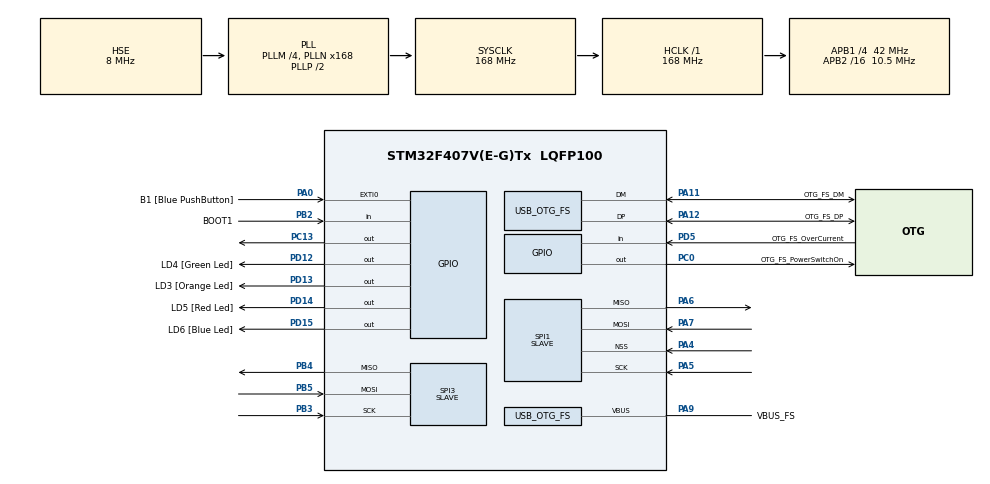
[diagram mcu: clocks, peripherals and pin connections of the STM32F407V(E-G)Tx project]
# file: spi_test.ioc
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Mcu.Family=STM32F4
Mcu.Name=STM32F407V(E-G)Tx
Mcu.Package=LQFP100
NVIC.OTG_FS_IRQn=true\:0\:0\:false\:false\:true\:true\:true\:true
NVIC.PriorityGroup=NVIC_PRIORITYGROUP_0
NVIC.TIM2_IRQn=true\:0\:0\:false\:false\:true\:true\:true\:true
PA0-WKUP.GPIO_Label=B1 [Blue PushButton]
PA0-WKUP.GPIO_ModeDefaultEXTI=GPIO_MODE_EVT_RISING
PA0-WKUP.GPIO_PuPd=GPIO_NOPULL
PA0-WKUP.Signal=GPXTI0
PA10.GPIO_Label=OTG_FS_ID
PA10.GPIO_Mode=GPIO_MODE_AF_PP
PA10.GPIO_PuPd=GPIO_NOPULL
PA10.GPIO_Speed=GPIO_SPEED_FREQ_LOW
PA10.Signal=USB_OTG_FS_ID
PA11.GPIO_Label=OTG_FS_DM
PA11.GPIO_Mode=GPIO_MODE_AF_PP
PA11.GPIO_PuPd=GPIO_NOPULL
PA11.GPIO_Speed=GPIO_SPEED_FREQ_LOW
PA11.Mode=Device_Only
PA11.Signal=USB_OTG_FS_DM
PA12.GPIO_Label=OTG_FS_DP
PA12.GPIO_Mode=GPIO_MODE_AF_PP
PA12.GPIO_PuPd=GPIO_NOPULL
PA12.GPIO_Speed=GPIO_SPEED_FREQ_LOW
PA12.Mode=Device_Only
PA12.Signal=USB_OTG_FS_DP
PA13.GPIO_Label=SWDIO
PA13.Signal=SYS_JTMS-SWDIO
PA4.GPIO_Speed=GPIO_SPEED_FREQ_LOW
PA4.Mode=NSS_Signal_Hard_Input
PA4.Signal=SPI1_NSS
PA5.GPIO_Speed=GPIO_SPEED_FREQ_LOW
PA5.Mode=Full_Duplex_Slave
PA5.Signal=SPI1_SCK
PA6.Mode=Full_Duplex_Slave
PA6.Signal=SPI1_MISO
PA7.GPIO_Speed=GPIO_SPEED_FREQ_LOW
PA7.Mode=Full_Duplex_Slave
PA7.Signal=SPI1_MOSI
PA9.GPIO_Label=VBUS_FS
PA9.GPIO_Mode=GPIO_MODE_INPUT
PA9.GPIO_PuPd=GPIO_NOPULL
PA9.Mode=Activate_VBUS
PA9.Signal=USB_OTG_FS_VBUS
PB2.GPIO_Label=BOOT1
PB2.GPIO_Mode=GPIO_MODE_INPUT
PB2.GPIO_PuPd=GPIO_NOPULL
PB2.Signal=GPIO_Input
PB3.Mode=Full_Duplex_Slave
PB3.Signal=SPI3_SCK
PB4.Mode=Full_Duplex_Slave
PB4.Signal=SPI3_MISO
PB5.Mode=Full_Duplex_Slave
PB5.Signal=SPI3_MOSI
PC0.GPIO_Label=OTG_FS_PowerSwitchOn
PC0.GPIO_PuPd=GPIO_NOPULL
PC0.GPIO_Speed=GPIO_SPEED_FREQ_LOW
PC0.PinState=GPIO_PIN_SET
PC0.Signal=GPIO_Output
PC13-ANTI_TAMP.Signal=GPIO_Output
PC14-OSC32_IN.GPIO_Label=PC14-OSC32_IN
PC14-OSC32_IN.Mode=LSE-External-Oscillator
PC14-OSC32_IN.Signal=RCC_OSC32_IN
PC15-OSC32_OUT.GPIO_Label=PC15-OSC32_OUT
PC15-OSC32_OUT.Mode=LSE-External-Oscillator
PC15-OSC32_OUT.Signal=RCC_OSC32_OUT
PC3.GPIO_Label=PDM_OUT [MP45DT02_DOUT]
PC3.GPIO_Mode=GPIO_MODE_AF_PP
PC3.GPIO_PuPd=GPIO_NOPULL
PC3.GPIO_Speed=GPIO_SPEED_FREQ_LOW
PC3.Signal=I2S2_SD
PD12.GPIO_Label=LD4 [Green Led]
PD12.GPIO_PuPd=GPIO_NOPULL
PD12.GPIO_Speed=GPIO_SPEED_FREQ_LOW
PD12.Signal=GPIO_Output
PD13.GPIO_Label=LD3 [Orange Led]
PD13.GPIO_PuPd=GPIO_NOPULL
PD13.GPIO_Speed=GPIO_SPEED_FREQ_LOW
PD13.Signal=GPIO_Output
PD14.GPIO_Label=LD5 [Red Led]
PD14.GPIO_PuPd=GPIO_NOPULL
PD14.GPIO_Speed=GPIO_SPEED_FREQ_LOW
PD14.Signal=GPIO_Output
PD15.GPIO_Label=LD6 [Blue Led]
PD15.GPIO_PuPd=GPIO_NOPULL
PD15.GPIO_Speed=GPIO_SPEED_FREQ_LOW
PD15.Signal=GPIO_Output
PD5.GPIO_Label=OTG_FS_OverCurrent
PD5.GPIO_Mode=GPIO_MODE_INPUT
PD5.GPIO_PuPd=GPIO_NOPULL
PD5.Signal=GPIO_Input
PH0-OSC_IN.GPIO_Label=PH0-OSC_IN
PH0-OSC_IN.Mode=HSE-External-Oscillator
PH0-OSC_IN.Signal=RCC_OSC_IN
PH1-OSC_OUT.GPIO_Label=PH1-OSC_OUT
PH1-OSC_OUT.Mode=HSE-External-Oscillator
PH1-OSC_OUT.Signal=RCC_OSC_OUT
ProjectManager.HeapSize=0x200
ProjectManager.StackSize=0x400
ProjectManager.TargetToolchain=STM32CubeIDE
RCC.48MHZClocksFreq_Value=48000000
RCC.AHBFreq_Value=168000000
RCC.APB1CLKDivider=RCC_HCLK_DIV4
RCC.APB1Freq_Value=42000000
RCC.APB1TimFreq_Value=84000000
RCC.APB2CLKDivider=RCC_HCLK_DIV16
RCC.APB2Freq_Value=10500000
RCC.APB2TimFreq_Value=21000000
RCC.CortexFreq_Value=168000000
RCC.HCLKFreq_Value=168000000
RCC.HSE_VALUE=8000000
RCC.HSI_VALUE=16000000
RCC.PLLM=4
RCC.PLLN=168
RCC.PLLQ=7
RCC.SYSCLKFreq_VALUE=168000000
RCC.SYSCLKSource=RCC_SYSCLKSOURCE_PLLCLK
RCC.VCOOutputFreq_Value=336000000
SPI1.Direction=SPI_DIRECTION_2LINES
SPI1.Mode=SPI_MODE_SLAVE
SPI1.VirtualNSS=VM_NSSHARD
SPI1.VirtualType=VM_SLAVE
SPI3.Direction=SPI_DIRECTION_2LINES
SPI3.Mode=SPI_MODE_SLAVE
SPI3.VirtualType=VM_SLAVE
USB_DEVICE.CLASS_NAME_FS=CDC
USB_DEVICE.VirtualMode-CDC_FS=Cdc
USB_DEVICE.VirtualModeFS=Cdc_FS
USB_OTG_FS.VirtualMode=Device_Only
VP_TIM2_VS_ClockSourceINT.Mode=Internal
VP_USB_DEVICE_VS_USB_DEVICE_CDC_FS.Mode=CDC_FS
board=STM32F407G-DISC1

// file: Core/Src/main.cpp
/* USER CODE BEGIN Header */
/**
  ******************************************************************************
  * @file           : main.c
  * @brief          : Main program body
  ******************************************************************************
  * @attention
  *
  * Copyright (c) 2023 STMicroelectronics.
  * All rights reserved.
  *
  * This software is licensed under terms that can be found in the LICENSE file
  * in the root directory of this software component.
  * If no LICENSE file comes with this software, it is provided AS-IS.
  *
  ******************************************************************************
  */
/* USER CODE END Header */
#include "main.h"
#include "usb_device.h"
#include "local.hpp"
#include "spi.hpp"

SPI_HandleTypeDef hspi1;
SPI_HandleTypeDef hspi3;
DMA_HandleTypeDef hdma_spi1_rx;
DMA_HandleTypeDef hdma_spi1_tx;

TIM_HandleTypeDef htim2;

void SystemClock_Config(void);
static void MX_GPIO_Init(void);
static void MX_DMA_Init(void);
static void MX_TIM2_Init(void);
static void MX_SPI1_Init(void);
static void MX_SPI3_Init(void);

int main(void)
{

  /* MCU Configuration--------------------------------------------------------*/

  /* Reset of all peripherals, Initializes the Flash interface and the Systick. */
  HAL_Init();

  /* Configure the system clock */
  SystemClock_Config();

  /* USER CODE END SysInit */

  /* Initialize all configured peripherals */
  MX_GPIO_Init();
  MX_DMA_Init();
  MX_USB_DEVICE_Init();
  MX_TIM2_Init();
  MX_SPI1_Init();
  MX_SPI3_Init();

  /* Infinite loop */
  /* USER CODE BEGIN WHILE */
  uint8_t tx = 0xAA;
  uint8_t rx = 0xBB;
  //uprintf("\r\n"); HAL_Delay(1000);
  for (int i=3; i>0; i--) {
    uprintf("slave start %d\r\n", i);
    HAL_GPIO_TogglePin(LD4_GPIO_Port, LD4_Pin); // green
    HAL_Delay(1000);
  }
  uprintf("\r\n"); HAL_Delay(1000);
  uprintf("\r\n"); HAL_Delay(1000);
  uprintf("\r\n"); HAL_Delay(1000);

  while (1)
  {
    /* USER CODE END WHILE */
    /* USER CODE BEGIN 3 */
      //HAL_GPIO_TogglePin(LD4_GPIO_Port, LD4_Pin); // green
      //HAL_GPIO_TogglePin(GPIOA, GPIO_PIN_6);
      //HAL_Delay(1000);
      PAL_SPI_TransmitReceive(&hspi1, &tx, &rx, 1, HAL_MAX_DELAY);
      uprintf("slave: tx=%d rx=%d -----------------------------------------------------------\r\n", tx, rx);
      HAL_GPIO_TogglePin(LD4_GPIO_Port, LD4_Pin); // green
      tx = rx;
  }
  /* USER CODE END 3 */
}

void SystemClock_Config(void)
{
  RCC_OscInitTypeDef RCC_OscInitStruct = {0};
  RCC_ClkInitTypeDef RCC_ClkInitStruct = {0};

  /** Configure the main internal regulator output voltage
  */
  __HAL_RCC_PWR_CLK_ENABLE();
  __HAL_PWR_VOLTAGESCALING_CONFIG(PWR_REGULATOR_VOLTAGE_SCALE1);

  /** Initializes the RCC Oscillators according to the specified parameters
  * in the RCC_OscInitTypeDef structure.
  */
  RCC_OscInitStruct.OscillatorType = RCC_OSCILLATORTYPE_HSE;
  RCC_OscInitStruct.HSEState = RCC_HSE_ON;
  RCC_OscInitStruct.PLL.PLLState = RCC_PLL_ON;
  RCC_OscInitStruct.PLL.PLLSource = RCC_PLLSOURCE_HSE;
  RCC_OscInitStruct.PLL.PLLM = 4;
  RCC_OscInitStruct.PLL.PLLN = 168;
  RCC_OscInitStruct.PLL.PLLP = RCC_PLLP_DIV2;
  RCC_OscInitStruct.PLL.PLLQ = 7;
  if (HAL_RCC_OscConfig(&RCC_OscInitStruct) != HAL_OK)
  {
    Error_Handler();
  }

  /** Initializes the CPU, AHB and APB buses clocks
  */
  RCC_ClkInitStruct.ClockType = RCC_CLOCKTYPE_HCLK|RCC_CLOCKTYPE_SYSCLK
                              |RCC_CLOCKTYPE_PCLK1|RCC_CLOCKTYPE_PCLK2;
  RCC_ClkInitStruct.SYSCLKSource = RCC_SYSCLKSOURCE_PLLCLK;
  RCC_ClkInitStruct.AHBCLKDivider = RCC_SYSCLK_DIV1;
  RCC_ClkInitStruct.APB1CLKDivider = RCC_HCLK_DIV4;
  RCC_ClkInitStruct.APB2CLKDivider = RCC_HCLK_DIV16;

  if (HAL_RCC_ClockConfig(&RCC_ClkInitStruct, FLASH_LATENCY_5) != HAL_OK)
  {
    Error_Handler();
  }
}

static void MX_SPI1_Init(void)
{

  /* SPI1 parameter configuration*/
  hspi1.Instance = SPI1;
  hspi1.Init.Mode = SPI_MODE_SLAVE;
  hspi1.Init.Direction = SPI_DIRECTION_2LINES;
  hspi1.Init.DataSize = SPI_DATASIZE_8BIT;
  //hspi1.Init.DataSize = SPI_DATASIZE_16BIT;
  hspi1.Init.CLKPolarity = SPI_POLARITY_LOW;
  hspi1.Init.CLKPhase = SPI_PHASE_1EDGE;
  hspi1.Init.NSS = SPI_NSS_HARD_INPUT;
  //hspi1.Init.NSS = SPI_NSS_SOFT;
  hspi1.Init.FirstBit = SPI_FIRSTBIT_MSB;
  hspi1.Init.TIMode = SPI_TIMODE_DISABLE;
  hspi1.Init.CRCCalculation = SPI_CRCCALCULATION_DISABLE;
  hspi1.Init.CRCPolynomial = 10;
  if (HAL_SPI_Init(&hspi1) != HAL_OK)
  {
    Error_Handler();
  }

}

static void MX_SPI3_Init(void)
{

  /* SPI3 parameter configuration*/
  hspi3.Instance = SPI3;
  hspi3.Init.Mode = SPI_MODE_SLAVE;
  hspi3.Init.Direction = SPI_DIRECTION_2LINES;
  hspi3.Init.DataSize = SPI_DATASIZE_8BIT;
  hspi3.Init.CLKPolarity = SPI_POLARITY_LOW;
  hspi3.Init.CLKPhase = SPI_PHASE_1EDGE;
  hspi3.Init.NSS = SPI_NSS_SOFT;
  hspi3.Init.FirstBit = SPI_FIRSTBIT_MSB;
  hspi3.Init.TIMode = SPI_TIMODE_DISABLE;
  hspi3.Init.CRCCalculation = SPI_CRCCALCULATION_DISABLE;
  hspi3.Init.CRCPolynomial = 10;
  if (HAL_SPI_Init(&hspi3) != HAL_OK)
  {
    Error_Handler();
  }

}

static void MX_TIM2_Init(void)
{

  TIM_ClockConfigTypeDef sClockSourceConfig = {0};
  TIM_MasterConfigTypeDef sMasterConfig = {0};

  htim2.Instance = TIM2;
  htim2.Init.Prescaler = 0;
  htim2.Init.CounterMode = TIM_COUNTERMODE_UP;
  htim2.Init.Period = 4294967295;
  htim2.Init.ClockDivision = TIM_CLOCKDIVISION_DIV1;
  htim2.Init.AutoReloadPreload = TIM_AUTORELOAD_PRELOAD_DISABLE;
  if (HAL_TIM_Base_Init(&htim2) != HAL_OK)
  {
    Error_Handler();
  }
  sClockSourceConfig.ClockSource = TIM_CLOCKSOURCE_INTERNAL;
  if (HAL_TIM_ConfigClockSource(&htim2, &sClockSourceConfig) != HAL_OK)
  {
    Error_Handler();
  }
  sMasterConfig.MasterOutputTrigger = TIM_TRGO_RESET;
  sMasterConfig.MasterSlaveMode = TIM_MASTERSLAVEMODE_DISABLE;
  if (HAL_TIMEx_MasterConfigSynchronization(&htim2, &sMasterConfig) != HAL_OK)
  {
    Error_Handler();
  }

}

static void MX_DMA_Init(void)
{

  /* DMA controller clock enable */
  __HAL_RCC_DMA2_CLK_ENABLE();

  /* DMA interrupt init */
  /* DMA2_Stream0_IRQn interrupt configuration */
  HAL_NVIC_SetPriority(DMA2_Stream0_IRQn, 0, 0);
  HAL_NVIC_EnableIRQ(DMA2_Stream0_IRQn);
  /* DMA2_Stream3_IRQn interrupt configuration */
  HAL_NVIC_SetPriority(DMA2_Stream3_IRQn, 0, 0);
  HAL_NVIC_EnableIRQ(DMA2_Stream3_IRQn);

}

static void MX_GPIO_Init(void)
{
  GPIO_InitTypeDef GPIO_InitStruct = {0};

  /* GPIO Ports Clock Enable */
  __HAL_RCC_GPIOE_CLK_ENABLE();
  __HAL_RCC_GPIOC_CLK_ENABLE();
  __HAL_RCC_GPIOH_CLK_ENABLE();
  __HAL_RCC_GPIOA_CLK_ENABLE();
  __HAL_RCC_GPIOB_CLK_ENABLE();
  __HAL_RCC_GPIOD_CLK_ENABLE();

  /*Configure GPIO pin Output Level */

  /*Configure GPIO pin Output Level */
  HAL_GPIO_WritePin(GPIOC, GPIO_PIN_13, GPIO_PIN_RESET);

  /*Configure GPIO pin Output Level */
  HAL_GPIO_WritePin(OTG_FS_PowerSwitchOn_GPIO_Port, OTG_FS_PowerSwitchOn_Pin, GPIO_PIN_SET);

  /*Configure GPIO pin Output Level */
  HAL_GPIO_WritePin(GPIOD, LD4_Pin|LD3_Pin|LD5_Pin|LD6_Pin, GPIO_PIN_RESET);

  /*Configure GPIO pins : PC13 OTG_FS_PowerSwitchOn_Pin */
  GPIO_InitStruct.Pin = GPIO_PIN_13|OTG_FS_PowerSwitchOn_Pin;
  GPIO_InitStruct.Mode = GPIO_MODE_OUTPUT_PP;
  GPIO_InitStruct.Pull = GPIO_NOPULL;
  GPIO_InitStruct.Speed = GPIO_SPEED_FREQ_LOW;
  HAL_GPIO_Init(GPIOC, &GPIO_InitStruct);

  /*Configure GPIO pin : PDM_OUT_Pin */
  GPIO_InitStruct.Pin = PDM_OUT_Pin;
  GPIO_InitStruct.Mode = GPIO_MODE_AF_PP;
  GPIO_InitStruct.Pull = GPIO_NOPULL;
  GPIO_InitStruct.Speed = GPIO_SPEED_FREQ_LOW;
  GPIO_InitStruct.Alternate = GPIO_AF5_SPI2;
  HAL_GPIO_Init(PDM_OUT_GPIO_Port, &GPIO_InitStruct);

  /*Configure GPIO pin : B1_Pin */
  GPIO_InitStruct.Pin = B1_Pin;
  GPIO_InitStruct.Mode = GPIO_MODE_EVT_RISING;
  GPIO_InitStruct.Pull = GPIO_NOPULL;
  HAL_GPIO_Init(B1_GPIO_Port, &GPIO_InitStruct);

  /*Configure GPIO pin : BOOT1_Pin */
  GPIO_InitStruct.Pin = BOOT1_Pin;
  GPIO_InitStruct.Mode = GPIO_MODE_INPUT;
  GPIO_InitStruct.Pull = GPIO_NOPULL;
  HAL_GPIO_Init(BOOT1_GPIO_Port, &GPIO_InitStruct);

  /*Configure GPIO pins : LD4_Pin LD3_Pin LD5_Pin LD6_Pin */
  GPIO_InitStruct.Pin = LD4_Pin|LD3_Pin|LD5_Pin|LD6_Pin;
  GPIO_InitStruct.Mode = GPIO_MODE_OUTPUT_PP;
  GPIO_InitStruct.Pull = GPIO_NOPULL;
  GPIO_InitStruct.Speed = GPIO_SPEED_FREQ_LOW;
  HAL_GPIO_Init(GPIOD, &GPIO_InitStruct);

  /*Configure GPIO pin : OTG_FS_OverCurrent_Pin */
  GPIO_InitStruct.Pin = OTG_FS_OverCurrent_Pin;
  GPIO_InitStruct.Mode = GPIO_MODE_INPUT;
  GPIO_InitStruct.Pull = GPIO_NOPULL;
  HAL_GPIO_Init(OTG_FS_OverCurrent_GPIO_Port, &GPIO_InitStruct);

}

void Error_Handler(void)
{
  __disable_irq();
  while (1)
  {
  }
}
